AUTOSAR XML (schema 4-0-3)
package /ComponentTypes
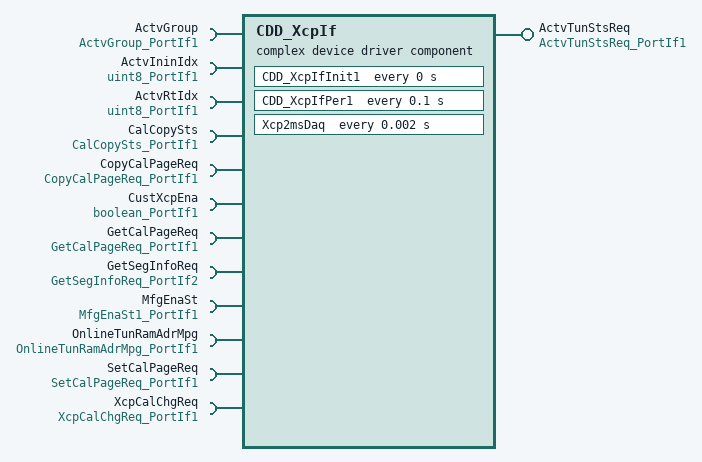
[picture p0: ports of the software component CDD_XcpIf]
  complex device driver sw component type CDD_XcpIf
    provide port ActvTunStsReq: server-com-spec{operation=Oper, queue-length=1}, provided-interface=ActvTunStsReq_PortIf1
    12 x require port:
      ActvGroup: nonqueued-receiver-com-spec{data-element=Val, filter=data-filter-type=ALWAYS, init-value=0}, required-interface=ActvGroup_PortIf1
      ActvIninIdx: nonqueued-receiver-com-spec{data-element=Val, filter=data-filter-type=ALWAYS, init-value=0}, required-interface=uint8_PortIf1
      ActvRtIdx: nonqueued-receiver-com-spec{data-element=Val, filter=data-filter-type=ALWAYS, init-value=0}, required-interface=uint8_PortIf1
      CalCopySts: nonqueued-receiver-com-spec{data-element=Val, filter=data-filter-type=ALWAYS, init-value=0}, required-interface=CalCopySts_PortIf1
      CopyCalPageReq: client-com-spec=Oper, required-interface=CopyCalPageReq_PortIf1
      CustXcpEna: nonqueued-receiver-com-spec{data-element=Logl, filter=data-filter-type=ALWAYS, init-value=0}, required-interface=boolean_PortIf1
      GetCalPageReq: client-com-spec=Oper, required-interface=GetCalPageReq_PortIf1
      GetSegInfoReq: client-com-spec=Oper, required-interface=GetSegInfoReq_PortIf2
      MfgEnaSt: nonqueued-receiver-com-spec{data-element=Val, filter=data-filter-type=ALWAYS, init-value=0}, required-interface=MfgEnaSt1_PortIf1
      OnlineTunRamAdrMpg: client-com-spec=Oper, required-interface=OnlineTunRamAdrMpg_PortIf1
      SetCalPageReq: client-com-spec=Oper, required-interface=SetCalPageReq_PortIf1
      XcpCalChgReq: client-com-spec=Oper, required-interface=XcpCalChgReq_PortIf1
    behavior CDD_XcpIf_InternalBehavior: data-type-mapping=Cals, port-api-option{enable-take-address=false, indirect-api=false, port=CustXcpEna}
      operation invoked event OIT_ActvTunStsReq_Oper_ActvTunStsReq_Oper: start-on-event=ActvTunStsReq_Oper, operation=ActvTunStsReq.Oper
      timing event CDD_XcpIf_InitEvent: start-on-event=CDD_XcpIfInit1, period=0
      timing event TMT_CDD_XcpIfPer1: start-on-event=CDD_XcpIfPer1, period=0.1
      timing event TMT_Xcp2msDaq: start-on-event=Xcp2msDaq, period=0.002
      4 x runnable:
        ActvTunStsReq_Oper
          data-receive-point-by-arguments:
            4 x access:
              REC_ActvGroup_Val: accessed-variable=ActvGroup.Val
              REC_ActvIninIdx_Val: accessed-variable=ActvIninIdx.Val
              REC_ActvRtIdx_Val: accessed-variable=ActvRtIdx.Val
              REC_CalCopySts_Val: accessed-variable=CalCopySts.Val
          sync call SC_XcpCalChgReq_Oper: operation=XcpCalChgReq.Oper, timeout=0
        CDD_XcpIfInit1
          data-receive-point-by-arguments:
            access REC_CustXcpEna_Logl: accessed-variable=CustXcpEna.Logl
            access REC_MfgEnaSt_Val: accessed-variable=MfgEnaSt.Val
          6 x sync call, all with timeout=0:
            SC_CopyCalPageReq_Oper: operation=CopyCalPageReq.Oper
            SC_GetCalPageReq_Oper: operation=GetCalPageReq.Oper
            SC_GetSegInfoReq_Oper: operation=GetSegInfoReq.Oper
            SC_OnlineTunRamAdrMpg_Oper: operation=OnlineTunRamAdrMpg.Oper
            SC_SetCalPageReq_Oper: operation=SetCalPageReq.Oper
            SC_XcpCalChgReq_Oper: operation=XcpCalChgReq.Oper
        CDD_XcpIfPer1
          data-receive-point-by-arguments:
            access REC_CustXcpEna_Logl: accessed-variable=CustXcpEna.Logl
            access REC_MfgEnaSt_Val: accessed-variable=MfgEnaSt.Val
        Xcp2msDaq
  swc implementation CDD_XcpIf_Implementation: behavior=CDD_XcpIf_InternalBehavior
    code-descriptors:
      code Default: artifact-descriptors=autosar-engineering-object={short-label=Default, category=SWSRC}
